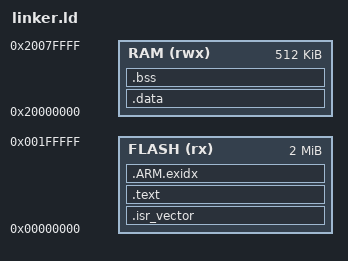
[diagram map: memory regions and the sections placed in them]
ENTRY(Reset_Handler)

MEMORY
{
  FLASH (rx) : ORIGIN = 0x00000000, LENGTH = 2048K
  RAM (rwx)  : ORIGIN = 0x20000000, LENGTH = 512K
}

_estack = ORIGIN(RAM) + LENGTH(RAM);

SECTIONS
{
  /* The vector table must be at the very start of FLASH */
  .isr_vector :
  {
    . = ALIGN(4);
    isr_vector = .;
    KEEP(*(.isr_vector))
    . = ALIGN(4);
  } > FLASH

  .text :
  {
    . = ALIGN(4);
    *(.text*)
    *(.rodata*)
    . = ALIGN(4);
  } > FLASH

  .ARM.exidx : 
  {
    __exidx_start = .;
    *(.ARM.exidx* .gnu.linkonce.armexidx.*)
    __exidx_end = .;
  } > FLASH

  _etext = .; 

  .data : AT ( _etext )
  {
    . = ALIGN(4);
    _sdata = .;
    *(.data*)
    . = ALIGN(4);
    _edata = .;
  } > RAM

  .bss :
  {
    . = ALIGN(4);
    _sbss = .;
    __bss_start__ = .;
    *(.bss*)
    *(COMMON)
    . = ALIGN(4);
    _ebss = .;
    __bss_end__ = .;
    end = .;
    _end = .;
  } > RAM
}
